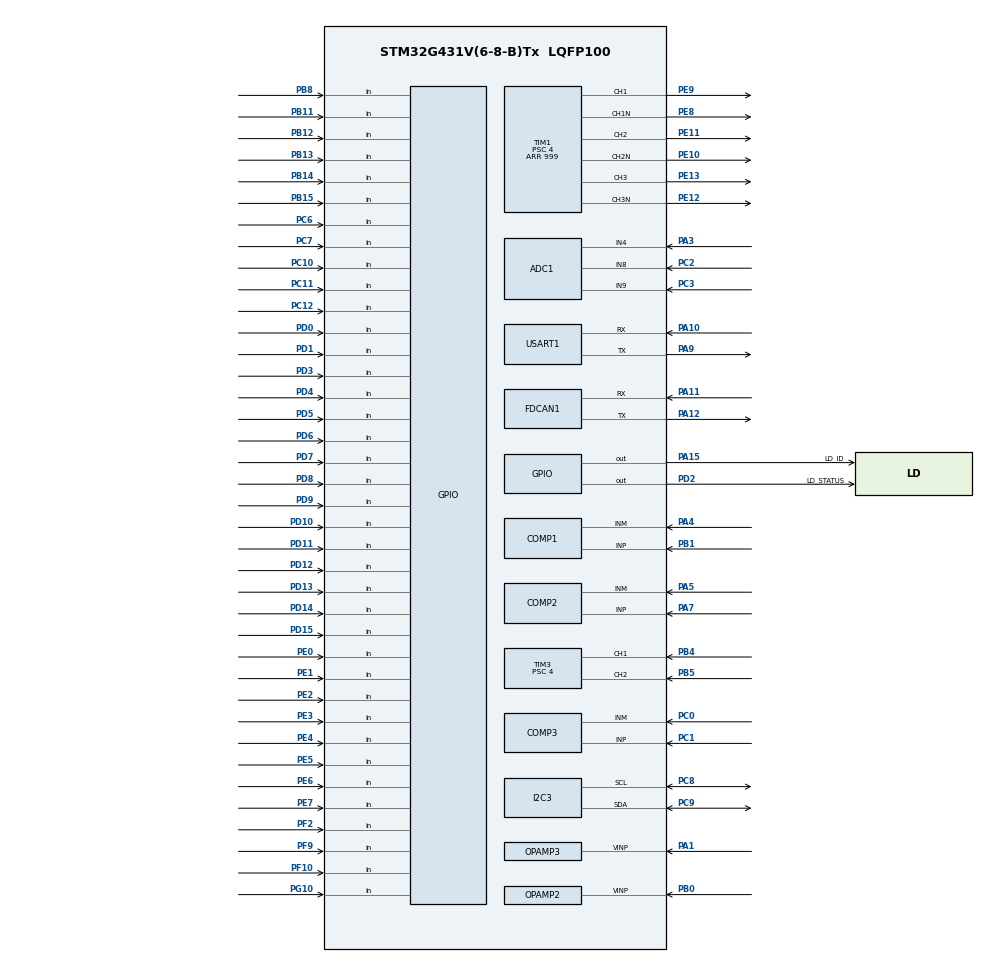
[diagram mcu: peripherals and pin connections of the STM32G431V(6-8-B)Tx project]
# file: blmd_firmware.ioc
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ADC1.Channel-4\#ChannelRegularConversion=ADC_CHANNEL_8
ADC1.Channel-5\#ChannelRegularConversion=ADC_CHANNEL_9
ADC1.Channel-6\#ChannelRegularConversion=ADC_CHANNEL_4
ADC1.ClockPrescaler=ADC_CLOCK_ASYNC_DIV8
ADC1.ContinuousConvMode=ENABLE
ADC1.DMAContinuousRequests=ENABLE
ADC1.EOCSelection=ADC_EOC_SEQ_CONV
ADC1.NbrOfConversion=3
ADC1.NbrOfConversionFlag=1
ADC1.OffsetNumber-4\#ChannelRegularConversion=ADC_OFFSET_NONE
ADC1.OffsetNumber-5\#ChannelRegularConversion=ADC_OFFSET_NONE
ADC1.OffsetNumber-6\#ChannelRegularConversion=ADC_OFFSET_NONE
ADC1.Rank-4\#ChannelRegularConversion=1
ADC1.Rank-5\#ChannelRegularConversion=2
ADC1.Rank-6\#ChannelRegularConversion=3
ADC1.SamplingTime-4\#ChannelRegularConversion=ADC_SAMPLETIME_12CYCLES_5
ADC1.SamplingTime-5\#ChannelRegularConversion=ADC_SAMPLETIME_12CYCLES_5
ADC1.SamplingTime-6\#ChannelRegularConversion=ADC_SAMPLETIME_12CYCLES_5
ADC1.master=1
ADC2.AWD1FilteringConfig=ADC_AWD_FILTERING_4SAMPLES
ADC2.AWD1HighThreshold=4000
ADC2.AWD1LowThreshold=96
ADC2.Channel-0\#ChannelRegularConversion=ADC_CHANNEL_VOPAMP2
ADC2.Channel-1\#ChannelRegularConversion=ADC_CHANNEL_VOPAMP3_ADC2
ADC2.ClockPrescaler=ADC_CLOCK_ASYNC_DIV8
ADC2.ContinuousConvMode=ENABLE
ADC2.DMAContinuousRequests=ENABLE
ADC2.EOCSelection=ADC_EOC_SEQ_CONV
ADC2.EnableAnalogWatchDog1=true
ADC2.EnableAnalogWatchDog2=false
ADC2.EnableAnalogWatchDog3=false
ADC2.NbrOfConversion=2
ADC2.NbrOfConversionFlag=1
ADC2.OffsetNumber-0\#ChannelRegularConversion=ADC_OFFSET_NONE
ADC2.OffsetNumber-1\#ChannelRegularConversion=ADC_OFFSET_NONE
ADC2.Rank-0\#ChannelRegularConversion=1
ADC2.Rank-1\#ChannelRegularConversion=2
ADC2.SamplingTime-0\#ChannelRegularConversion=ADC_SAMPLETIME_12CYCLES_5
ADC2.SamplingTime-1\#ChannelRegularConversion=ADC_SAMPLETIME_12CYCLES_5
ADC2.WatchdogMode=ADC_ANALOGWATCHDOG_ALL_REG
COMP1.BlankingSrce=COMP_BLANKINGSRC_NONE
COMP1.Hysteresis=COMP_HYSTERESIS_70MV
COMP1.TriggerMode=COMP_TRIGGERMODE_IT_RISING_FALLING
COMP2.BlankingSrce=COMP_BLANKINGSRC_NONE
COMP2.Hysteresis=COMP_HYSTERESIS_70MV
COMP2.TriggerMode=COMP_TRIGGERMODE_IT_RISING_FALLING
COMP3.BlankingSrce=COMP_BLANKINGSRC_NONE
COMP3.Hysteresis=COMP_HYSTERESIS_70MV
COMP3.TriggerMode=COMP_TRIGGERMODE_IT_RISING_FALLING
Dma.ADC1.0.Direction=DMA_PERIPH_TO_MEMORY
Dma.ADC1.0.EventEnable=DISABLE
Dma.ADC1.0.Instance=DMA1_Channel4
Dma.ADC1.0.MemDataAlignment=DMA_MDATAALIGN_HALFWORD
Dma.ADC1.0.MemInc=DMA_MINC_ENABLE
Dma.ADC1.0.Mode=DMA_CIRCULAR
Dma.ADC1.0.PeriphDataAlignment=DMA_PDATAALIGN_HALFWORD
Dma.ADC1.0.PeriphInc=DMA_PINC_DISABLE
Dma.ADC1.0.Polarity=HAL_DMAMUX_REQ_GEN_RISING
Dma.ADC1.0.Priority=DMA_PRIORITY_LOW
Dma.ADC1.0.RequestNumber=1
Dma.ADC1.0.SignalID=NONE
Dma.ADC1.0.SyncEnable=DISABLE
Dma.ADC1.0.SyncPolarity=HAL_DMAMUX_SYNC_NO_EVENT
Dma.ADC1.0.SyncRequestNumber=1
Dma.ADC1.0.SyncSignalID=NONE
Dma.ADC2.1.Direction=DMA_PERIPH_TO_MEMORY
Dma.ADC2.1.EventEnable=DISABLE
Dma.ADC2.1.Instance=DMA1_Channel1
Dma.ADC2.1.MemDataAlignment=DMA_MDATAALIGN_HALFWORD
Dma.ADC2.1.MemInc=DMA_MINC_ENABLE
Dma.ADC2.1.Mode=DMA_CIRCULAR
Dma.ADC2.1.PeriphDataAlignment=DMA_PDATAALIGN_HALFWORD
Dma.ADC2.1.PeriphInc=DMA_PINC_DISABLE
Dma.ADC2.1.Polarity=HAL_DMAMUX_REQ_GEN_RISING
Dma.ADC2.1.Priority=DMA_PRIORITY_LOW
Dma.ADC2.1.RequestNumber=1
Dma.ADC2.1.SignalID=NONE
Dma.ADC2.1.SyncEnable=DISABLE
Dma.ADC2.1.SyncPolarity=HAL_DMAMUX_SYNC_NO_EVENT
Dma.ADC2.1.SyncRequestNumber=1
Dma.ADC2.1.SyncSignalID=NONE
Dma.FMAC_READ.2.Direction=DMA_PERIPH_TO_MEMORY
Dma.FMAC_READ.2.EventEnable=DISABLE
Dma.FMAC_READ.2.Instance=DMA1_Channel3
Dma.FMAC_READ.2.MemDataAlignment=DMA_MDATAALIGN_HALFWORD
Dma.FMAC_READ.2.MemInc=DMA_MINC_ENABLE
Dma.FMAC_READ.2.Mode=DMA_CIRCULAR
Dma.FMAC_READ.2.PeriphDataAlignment=DMA_PDATAALIGN_WORD
Dma.FMAC_READ.2.PeriphInc=DMA_PINC_DISABLE
Dma.FMAC_READ.2.Polarity=HAL_DMAMUX_REQ_GEN_RISING
Dma.FMAC_READ.2.Priority=DMA_PRIORITY_LOW
Dma.FMAC_READ.2.RequestNumber=1
Dma.FMAC_READ.2.SignalID=NONE
Dma.FMAC_READ.2.SyncEnable=DISABLE
Dma.FMAC_READ.2.SyncPolarity=HAL_DMAMUX_SYNC_NO_EVENT
Dma.FMAC_READ.2.SyncRequestNumber=1
Dma.FMAC_READ.2.SyncSignalID=NONE
Dma.FMAC_WRITE.3.Direction=DMA_MEMORY_TO_PERIPH
Dma.FMAC_WRITE.3.EventEnable=DISABLE
Dma.FMAC_WRITE.3.Instance=DMA1_Channel2
Dma.FMAC_WRITE.3.MemDataAlignment=DMA_MDATAALIGN_HALFWORD
Dma.FMAC_WRITE.3.MemInc=DMA_MINC_ENABLE
Dma.FMAC_WRITE.3.Mode=DMA_NORMAL
Dma.FMAC_WRITE.3.PeriphDataAlignment=DMA_PDATAALIGN_WORD
Dma.FMAC_WRITE.3.PeriphInc=DMA_PINC_DISABLE
Dma.FMAC_WRITE.3.Polarity=HAL_DMAMUX_REQ_GEN_RISING
Dma.FMAC_WRITE.3.Priority=DMA_PRIORITY_LOW
Dma.FMAC_WRITE.3.RequestNumber=1
Dma.FMAC_WRITE.3.SignalID=NONE
Dma.FMAC_WRITE.3.SyncEnable=DISABLE
Dma.FMAC_WRITE.3.SyncPolarity=HAL_DMAMUX_SYNC_NO_EVENT
Dma.FMAC_WRITE.3.SyncRequestNumber=1
Dma.FMAC_WRITE.3.SyncSignalID=NONE
Dma.Request0=ADC1
Dma.Request1=ADC2
Dma.Request2=FMAC_READ
Dma.Request3=FMAC_WRITE
FDCAN1.CalculateBaudRateNominal=1000000
FDCAN1.CalculateTimeBitNominal=1000
FDCAN1.CalculateTimeQuantumNominal=100.0
FDCAN1.NominalTimeSeg1=6
FDCAN1.NominalTimeSeg2=3
I2C3.Timing=0x30D29DE4
Mcu.Family=STM32G4
Mcu.Name=STM32G431V(6-8-B)Tx
Mcu.Package=LQFP100
NVIC.COMP1_2_3_IRQn=true\:0\:0\:false\:false\:true\:false\:true\:true
NVIC.PriorityGroup=NVIC_PRIORITYGROUP_4
NVIC.TIM1_UP_TIM16_IRQn=true\:0\:0\:false\:false\:true\:true\:true\:true
NVIC.TIM6_DAC_IRQn=true\:0\:0\:false\:false\:true\:true\:true\:true
PA1.Mode=PGA_Internally_Connected
PA1.Signal=OPAMP3_VINP
PA10.Mode=Asynchronous
PA10.Signal=USART1_RX
PA11.Mode=FDCAN_Activate
PA11.Signal=FDCAN1_RX
PA12.Mode=FDCAN_Activate
PA12.Signal=FDCAN1_TX
PA13.Mode=Trace_Asynchronous_SW
PA13.Signal=SYS_JTMS-SWDIO
PA14.Mode=Trace_Asynchronous_SW
PA14.Signal=SYS_JTCK-SWCLK
PA15.GPIO_Label=LD_ID
PA15.Signal=GPIO_Output
PA3.Mode=IN4-Single-Ended
PA3.Signal=ADC1_IN4
PA4.Mode=INM
PA4.Signal=COMP1_INM
PA5.Mode=INM
PA5.Signal=COMP2_INM
PA7.Mode=INP
PA7.Signal=COMP2_INP
PA9.Mode=Asynchronous
PA9.Signal=USART1_TX
PB0.Mode=Follower_Internally_Connected
PB0.Signal=OPAMP2_VINP
PB1.Mode=INP
PB1.Signal=COMP1_INP
PB11.Signal=GPIO_Input
PB12.Signal=GPIO_Input
PB13.Signal=GPIO_Input
PB14.Signal=GPIO_Input
PB15.Signal=GPIO_Input
PB3.Mode=Trace_Asynchronous_SW
PB3.Signal=SYS_JTDO-SWO
PB4.Signal=S_TIM3_CH1
PB5.Signal=S_TIM3_CH2
PB8-BOOT0.Signal=GPIO_Input
PC0.Mode=INM
PC0.Signal=COMP3_INM
PC1.Mode=INP
PC1.Signal=COMP3_INP
PC10.Signal=GPIO_Input
PC11.Signal=GPIO_Input
PC12.Signal=GPIO_Input
PC2.Mode=IN8-Single-Ended
PC2.Signal=ADC1_IN8
PC3.Mode=IN9-Single-Ended
PC3.Signal=ADC1_IN9
PC6.Signal=GPIO_Input
PC7.Signal=GPIO_Input
PC8.Mode=I2C
PC8.Signal=I2C3_SCL
PC9.Mode=I2C
PC9.Signal=I2C3_SDA
PD0.Signal=GPIO_Input
PD1.Signal=GPIO_Input
PD10.Signal=GPIO_Input
PD11.Signal=GPIO_Input
PD12.Signal=GPIO_Input
PD13.Signal=GPIO_Input
PD14.Signal=GPIO_Input
PD15.Signal=GPIO_Input
PD2.GPIO_Label=LD_STATUS
PD2.Signal=GPIO_Output
PD3.Signal=GPIO_Input
PD4.Signal=GPIO_Input
PD5.Signal=GPIO_Input
PD6.Signal=GPIO_Input
PD7.Signal=GPIO_Input
PD8.Signal=GPIO_Input
PD9.Signal=GPIO_Input
PE0.Signal=GPIO_Input
PE1.Signal=GPIO_Input
PE10.Mode=PWM Generation2 CH2 CH2N
PE10.Signal=TIM1_CH2N
PE11.Signal=S_TIM1_CH2
PE12.Mode=PWM Generation3 CH3 CH3N
PE12.Signal=TIM1_CH3N
PE13.Signal=S_TIM1_CH3
PE2.Signal=GPIO_Input
PE3.Signal=GPIO_Input
PE4.Signal=GPIO_Input
PE5.Signal=GPIO_Input
PE6.Signal=GPIO_Input
PE7.Signal=GPIO_Input
PE8.Mode=PWM Generation1 CH1 CH1N
PE8.Signal=TIM1_CH1N
PE9.Signal=S_TIM1_CH1
PF10.Signal=GPIO_Input
PF2.Signal=GPIO_Input
PF9.Signal=GPIO_Input
PG10-NRST.Signal=GPIO_Input
ProjectManager.HeapSize=0x200
ProjectManager.StackSize=0x400
ProjectManager.TargetToolchain=CMake
RCC.ADC12Freq_Value=160000000
RCC.AHBFreq_Value=160000000
RCC.APB1Freq_Value=160000000
RCC.APB1TimFreq_Value=160000000
RCC.APB2Freq_Value=160000000
RCC.APB2TimFreq_Value=160000000
RCC.CortexFreq_Value=160000000
RCC.EXTERNAL_CLOCK_VALUE=12288000
RCC.HCLKFreq_Value=160000000
RCC.HSE_VALUE=8000000
RCC.HSI48_VALUE=48000000
RCC.HSI_VALUE=16000000
RCC.LSE_VALUE=32768
RCC.PLLN=20
RCC.SYSCLKFreq_VALUE=160000000
RCC.SYSCLKSource=RCC_SYSCLKSOURCE_PLLCLK
RCC.USBFreq_Value=160000000
RCC.VCOOutputFreq_Value=320000000
SH.S_TIM1_CH1.0=TIM1_CH1,PWM Generation1 CH1 CH1N
SH.S_TIM1_CH2.0=TIM1_CH2,PWM Generation2 CH2 CH2N
SH.S_TIM1_CH3.0=TIM1_CH3,PWM Generation3 CH3 CH3N
SH.S_TIM3_CH1.0=TIM3_CH1,Input_Capture1_from_TI1
SH.S_TIM3_CH2.0=TIM3_CH2,Input_Capture2_from_TI2
TIM1.Channel-PWM\ Generation1\ CH1\ CH1N=TIM_CHANNEL_1
TIM1.Channel-PWM\ Generation2\ CH2\ CH2N=TIM_CHANNEL_2
TIM1.Channel-PWM\ Generation3\ CH3\ CH3N=TIM_CHANNEL_3
TIM1.DeadTime=128
TIM1.PeriodNoDither=999
TIM1.Prescaler=4
TIM1.TIM_MasterOutputTrigger=TIM_TRGO_RESET
TIM3.Channel-Input_Capture1_from_TI1=TIM_CHANNEL_1
TIM3.Channel-Input_Capture2_from_TI2=TIM_CHANNEL_2
TIM3.PeriodNoDither=999
TIM3.Prescaler=4
TIM6.PeriodNoDither=999
TIM6.Prescaler=4
USART1.VirtualMode-Asynchronous=VM_ASYNC
VP_ADC2_OPAMP_INTERNAL2.Mode=IN-OPAMP2
VP_ADC2_OPAMP_INTERNAL3.Mode=IN-OPAMP3
VP_CORDIC_VS_CORDIC.Mode=CORDIC_Activate
VP_FMAC_VS_FMAC.Mode=FMAC_Activate
VP_SYS_VS_DBSignals.Mode=DisableDeadBatterySignals
VP_TIM6_VS_ClockSourceINT.Mode=Enable_Timer
board=custom

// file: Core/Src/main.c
/* USER CODE BEGIN Header */
/**
  ******************************************************************************
  * @file           : main.c
  * @brief          : Main program body
  ******************************************************************************
  * @attention
  *
  * Copyright (c) 2024 STMicroelectronics.
  * All rights reserved.
  *
  * This software is licensed under terms that can be found in the LICENSE file
  * in the root directory of this software component.
  * If no LICENSE file comes with this software, it is provided AS-IS.
  *
  ******************************************************************************
  */
/* USER CODE END Header */
#include "main.h"

/* USER CODE BEGIN Includes */
#include "stdio.h"
#include "stdlib.h"
#include "math.h"

#include "foc.h"
/* USER CODE END Includes */

/* USER CODE BEGIN PD */
#define I2C_ADD 0x47
/* USER CODE END PD */

FDCAN_HandleTypeDef hfdcan1;

/* USER CODE BEGIN PV */
/* for PI control valuables */
RingBuf pi_u;		//control values
RingBuf pi_e;		//deviation
RingBuf omg_est;	//omg estimate

volatile int32_t omg_tgt = 0;		//fixed float 22.10[rad/ms]
volatile int32_t adv_ang = 0;		//fixed float 22.10[rad]
volatile int32_t rot_est = 0;		//fixed float 22.10[rad]

volatile int32_t omg_est2 = 0;		//fixed float 22.10[rad/ms]
volatile int32_t rot_est2 = 0;		//fixed float 22.10[rad]

volatile uint8_t rot_direct = 0;

/* for FMAC valuables */
volatile uint16_t adc_datas[ADC_BUF] = {0u};
volatile uint16_t y_buffer[2] = {0u};
float current[2] = {0u};
uint8_t dma_index = 0u;
uint32_t detect_flag = 0;
/* USER CODE END PV */

void SystemClock_Config(void);
static void MX_GPIO_Init(void);
static void MX_DMA_Init(void);
static void MX_COMP1_Init(void);
static void MX_COMP2_Init(void);
static void MX_COMP3_Init(void);
static void MX_OPAMP2_Init(void);
static void MX_FDCAN1_Init(void);
static void MX_USART1_UART_Init(void);
static void MX_ADC1_Init(void);
static void MX_ADC2_Init(void);
static void MX_I2C3_Init(void);
static void MX_OPAMP3_Init(void);
static void MX_TIM1_Init(void);
static void MX_TIM3_Init(void);
static void MX_CORDIC_Init(void);
static void MX_FMAC_Init(void);
static void MX_TIM6_Init(void);

int main(void)
{

  /* USER CODE BEGIN 1 */

	pi_u.pnt = 0;
	pi_e.pnt = 0;
	for(int8_t i = 0; i<4;i++){
		pi_u.data[i] = 100<<10;
		pi_e.data[i] = 0;
	}
  /* USER CODE END 1 */

  /* MCU Configuration--------------------------------------------------------*/

  /* Reset of all peripherals, Initializes the Flash interface and the Systick. */
  HAL_Init();

  /* Configure the system clock */
  SystemClock_Config();

  /* Initialize all configured peripherals */
  MX_GPIO_Init();
  MX_DMA_Init();
  MX_COMP1_Init();
  MX_COMP2_Init();
  MX_COMP3_Init();
  MX_OPAMP2_Init();
  MX_FDCAN1_Init();
  MX_USART1_UART_Init();
  MX_ADC1_Init();
  MX_ADC2_Init();
  MX_I2C3_Init();
  MX_OPAMP3_Init();
  MX_TIM1_Init();
  MX_TIM3_Init();
  MX_CORDIC_Init();
  MX_FMAC_Init();
  MX_TIM6_Init();
  /* USER CODE BEGIN 2 */
	adc_setup();

	LL_OPAMP_Enable(OPAMP2);
	LL_OPAMP_Enable(OPAMP3);

	LL_COMP_Enable(COMP1);
	LL_COMP_Enable(COMP2);
	LL_COMP_Enable(COMP3);

	LL_TIM_EnableCounter(TIM1);
	LL_TIM_EnableARRPreload(TIM1);
	LL_TIM_EnableAllOutputs(TIM1);

	LL_TIM_CC_EnableChannel(TIM1, LL_TIM_CHANNEL_CH1);
	LL_TIM_CC_EnableChannel(TIM1, LL_TIM_CHANNEL_CH1N);
	LL_TIM_OC_SetCompareCH1(TIM1, 200);

	// start gate driver
	LL_I2C_Enable(I2C3);

	LL_I2C_HandleTransfer(I2C3, 0x47, LL_I2C_ADDRESSING_MODE_7BIT, 1, LL_I2C_MODE_AUTOEND, LL_I2C_GENERATE_START_WRITE);
	while(!LL_I2C_IsActiveFlag_TXE(I2C3));
	LL_I2C_TransmitData8(I2C3, 0x80);

	LL_I2C_HandleTransfer(I2C3, 0x47, LL_I2C_ADDRESSING_MODE_7BIT, 1, LL_I2C_MODE_AUTOEND, LL_I2C_GENERATE_START_READ);
	while(LL_I2C_IsActiveFlag_RXNE(I2C3));
	uint8_t i2c_buf = LL_I2C_ReceiveData8(I2C3);

	if(i2c_buf & 0x04){
		LL_GPIO_SetOutputPin(LD_ID_GPIO_Port, LD_ID_Pin);
	}

	LL_mDelay(1000);

	startSequence();

	LL_mDelay(2000);

	rot_direct = 0;
	omg_tgt = (uint32_t)(45.0*M_PI/100.0f * 1024.0f);
  	omg_est2 = (uint32_t)(7.0*M_PI/100.0f * 1024.0f);
	adv_ang = (uint32_t)(0.0*M_PI/180.0f * 1024);
	rot_est2 = (uint32_t)( 60*M_PI/180*1024);
	detect_flag = 1;
	LL_EXTI_DisableRisingTrig_0_31(LL_EXTI_LINE_21);
	LL_EXTI_DisableFallingTrig_0_31(LL_EXTI_LINE_21);
	LL_EXTI_DisableRisingTrig_0_31(LL_EXTI_LINE_22);
	LL_EXTI_DisableFallingTrig_0_31(LL_EXTI_LINE_22);
	LL_EXTI_DisableRisingTrig_0_31(LL_EXTI_LINE_29);
	LL_EXTI_DisableFallingTrig_0_31(LL_EXTI_LINE_29);
	LL_TIM_EnableCounter(TIM6);
	LL_TIM_EnableIT_UPDATE(TIM6);
  /* USER CODE END 2 */

  /* Infinite loop */
  /* USER CODE BEGIN WHILE */
  while (1)
  {
	LL_mDelay(300);
	if(omg_est2 <= omg_tgt*5/6){
		omg_est2 += omg_tgt/10;
	}

	if((omg_tgt-omg_est.data[(omg_est.pnt+3)&0x03]) < 50){
		LL_GPIO_TogglePin(LD_STATUS_GPIO_Port, LD_STATUS_Pin);
	}
//	LL_I2C_HandleTransfer(I2C3, 0x47, LL_I2C_ADDRESSING_MODE_7BIT, 1, LL_I2C_MODE_AUTOEND, LL_I2C_GENERATE_START_WRITE);
//	while(!LL_I2C_IsActiveFlag_TXE(I2C3));
//	LL_I2C_TransmitData8(I2C3, 0x80);
//
//	LL_I2C_HandleTransfer(I2C3, 0x47, LL_I2C_ADDRESSING_MODE_7BIT, 1, LL_I2C_MODE_AUTOEND, LL_I2C_GENERATE_START_READ);
//	while(LL_I2C_IsActiveFlag_RXNE(I2C3));
//	i2c_buf = LL_I2C_ReceiveData8(I2C3);
//
//	if(i2c_buf){
//		LL_GPIO_SetOutputPin(LD_ID_GPIO_Port, LD_ID_Pin);
//	}

	char str[16];
	sprintf(str, "%d\n" , (int)(omg_est.data[0]+omg_est.data[1]+omg_est.data[2]+omg_est.data[3])>>2);
	for(uint8_t i=0;str[i] != '\0'; i++){
		ITM_SendChar(str[i]);
	}
    /* USER CODE END WHILE */

  }
}

void SystemClock_Config(void)
{
  LL_FLASH_SetLatency(LL_FLASH_LATENCY_4);
  while(LL_FLASH_GetLatency() != LL_FLASH_LATENCY_4)
  {
  }
  LL_PWR_EnableRange1BoostMode();
  LL_RCC_HSI_Enable();
   /* Wait till HSI is ready */
  while(LL_RCC_HSI_IsReady() != 1)
  {
  }

  LL_RCC_HSI_SetCalibTrimming(64);
  LL_RCC_PLL_ConfigDomain_SYS(LL_RCC_PLLSOURCE_HSI, LL_RCC_PLLM_DIV_1, 20, LL_RCC_PLLR_DIV_2);
  LL_RCC_PLL_EnableDomain_SYS();
  LL_RCC_PLL_Enable();
   /* Wait till PLL is ready */
  while(LL_RCC_PLL_IsReady() != 1)
  {
  }

  LL_RCC_SetSysClkSource(LL_RCC_SYS_CLKSOURCE_PLL);
  LL_RCC_SetAHBPrescaler(LL_RCC_SYSCLK_DIV_2);
   /* Wait till System clock is ready */
  while(LL_RCC_GetSysClkSource() != LL_RCC_SYS_CLKSOURCE_STATUS_PLL)
  {
  }

  /* Insure 1us transition state at intermediate medium speed clock*/
  for (__IO uint32_t i = (170 >> 1); i !=0; i--);

  /* Set AHB prescaler*/
  LL_RCC_SetAHBPrescaler(LL_RCC_SYSCLK_DIV_1);
  LL_RCC_SetAPB1Prescaler(LL_RCC_APB1_DIV_1);
  LL_RCC_SetAPB2Prescaler(LL_RCC_APB2_DIV_1);
  LL_SetSystemCoreClock(160000000);

   /* Update the time base */
  if (HAL_InitTick (TICK_INT_PRIORITY) != HAL_OK)
  {
    Error_Handler();
  }
}

static void MX_ADC1_Init(void)
{

  LL_ADC_InitTypeDef ADC_InitStruct = {0};
  LL_ADC_REG_InitTypeDef ADC_REG_InitStruct = {0};
  LL_ADC_CommonInitTypeDef ADC_CommonInitStruct = {0};

  LL_GPIO_InitTypeDef GPIO_InitStruct = {0};

  LL_RCC_SetADCClockSource(LL_RCC_ADC12_CLKSOURCE_SYSCLK);

  /* Peripheral clock enable */
  LL_AHB2_GRP1_EnableClock(LL_AHB2_GRP1_PERIPH_ADC12);

  LL_AHB2_GRP1_EnableClock(LL_AHB2_GRP1_PERIPH_GPIOC);
  LL_AHB2_GRP1_EnableClock(LL_AHB2_GRP1_PERIPH_GPIOA);
  /**ADC1 GPIO Configuration
  PC2   ------> ADC1_IN8
  PC3   ------> ADC1_IN9
  PA3   ------> ADC1_IN4
  */
  GPIO_InitStruct.Pin = LL_GPIO_PIN_2;
  GPIO_InitStruct.Mode = LL_GPIO_MODE_ANALOG;
  GPIO_InitStruct.Pull = LL_GPIO_PULL_NO;
  LL_GPIO_Init(GPIOC, &GPIO_InitStruct);

  GPIO_InitStruct.Pin = LL_GPIO_PIN_3;
  GPIO_InitStruct.Mode = LL_GPIO_MODE_ANALOG;
  GPIO_InitStruct.Pull = LL_GPIO_PULL_NO;
  LL_GPIO_Init(GPIOC, &GPIO_InitStruct);

  GPIO_InitStruct.Pin = LL_GPIO_PIN_3;
  GPIO_InitStruct.Mode = LL_GPIO_MODE_ANALOG;
  GPIO_InitStruct.Pull = LL_GPIO_PULL_NO;
  LL_GPIO_Init(GPIOA, &GPIO_InitStruct);

  /* ADC1 DMA Init */

  /* ADC1 Init */
  LL_DMA_SetPeriphRequest(DMA1, LL_DMA_CHANNEL_4, LL_DMAMUX_REQ_ADC1);

  LL_DMA_SetDataTransferDirection(DMA1, LL_DMA_CHANNEL_4, LL_DMA_DIRECTION_PERIPH_TO_MEMORY);

  LL_DMA_SetChannelPriorityLevel(DMA1, LL_DMA_CHANNEL_4, LL_DMA_PRIORITY_LOW);

  LL_DMA_SetMode(DMA1, LL_DMA_CHANNEL_4, LL_DMA_MODE_CIRCULAR);

  LL_DMA_SetPeriphIncMode(DMA1, LL_DMA_CHANNEL_4, LL_DMA_PERIPH_NOINCREMENT);

  LL_DMA_SetMemoryIncMode(DMA1, LL_DMA_CHANNEL_4, LL_DMA_MEMORY_INCREMENT);

  LL_DMA_SetPeriphSize(DMA1, LL_DMA_CHANNEL_4, LL_DMA_PDATAALIGN_HALFWORD);

  LL_DMA_SetMemorySize(DMA1, LL_DMA_CHANNEL_4, LL_DMA_MDATAALIGN_HALFWORD);

  /** Common config
  */
  ADC_InitStruct.Resolution = LL_ADC_RESOLUTION_12B;
  ADC_InitStruct.DataAlignment = LL_ADC_DATA_ALIGN_RIGHT;
  ADC_InitStruct.LowPowerMode = LL_ADC_LP_MODE_NONE;
  LL_ADC_Init(ADC1, &ADC_InitStruct);
  ADC_REG_InitStruct.TriggerSource = LL_ADC_REG_TRIG_SOFTWARE;
  ADC_REG_InitStruct.SequencerLength = LL_ADC_REG_SEQ_SCAN_ENABLE_3RANKS;
  ADC_REG_InitStruct.SequencerDiscont = LL_ADC_REG_SEQ_DISCONT_DISABLE;
  ADC_REG_InitStruct.ContinuousMode = LL_ADC_REG_CONV_CONTINUOUS;
  ADC_REG_InitStruct.DMATransfer = LL_ADC_REG_DMA_TRANSFER_UNLIMITED;
  ADC_REG_InitStruct.Overrun = LL_ADC_REG_OVR_DATA_PRESERVED;
  LL_ADC_REG_Init(ADC1, &ADC_REG_InitStruct);
  LL_ADC_SetGainCompensation(ADC1, 0);
  LL_ADC_SetOverSamplingScope(ADC1, LL_ADC_OVS_DISABLE);
  ADC_CommonInitStruct.CommonClock = LL_ADC_CLOCK_ASYNC_DIV8;
  ADC_CommonInitStruct.Multimode = LL_ADC_MULTI_INDEPENDENT;
  LL_ADC_CommonInit(__LL_ADC_COMMON_INSTANCE(ADC1), &ADC_CommonInitStruct);

  /* Disable ADC deep power down (enabled by default after reset state) */
  LL_ADC_DisableDeepPowerDown(ADC1);
  /* Enable ADC internal voltage regulator */
  LL_ADC_EnableInternalRegulator(ADC1);
  /* Delay for ADC internal voltage regulator stabilization. */
  /* Compute number of CPU cycles to wait for, from delay in us. */
  /* Note: Variable divided by 2 to compensate partially */
  /* CPU processing cycles (depends on compilation optimization). */
  /* Note: If system core clock frequency is below 200kHz, wait time */
  /* is only a few CPU processing cycles. */
  uint32_t wait_loop_index;
  wait_loop_index = ((LL_ADC_DELAY_INTERNAL_REGUL_STAB_US * (SystemCoreClock / (100000 * 2))) / 10);
  while(wait_loop_index != 0)
  {
    wait_loop_index--;
  }

  /** Configure Regular Channel
  */
  LL_ADC_REG_SetSequencerRanks(ADC1, LL_ADC_REG_RANK_1, LL_ADC_CHANNEL_8);
  LL_ADC_SetChannelSamplingTime(ADC1, LL_ADC_CHANNEL_8, LL_ADC_SAMPLINGTIME_12CYCLES_5);
  LL_ADC_SetChannelSingleDiff(ADC1, LL_ADC_CHANNEL_8, LL_ADC_SINGLE_ENDED);

  /** Configure Regular Channel
  */
  LL_ADC_REG_SetSequencerRanks(ADC1, LL_ADC_REG_RANK_2, LL_ADC_CHANNEL_9);
  LL_ADC_SetChannelSamplingTime(ADC1, LL_ADC_CHANNEL_9, LL_ADC_SAMPLINGTIME_12CYCLES_5);
  LL_ADC_SetChannelSingleDiff(ADC1, LL_ADC_CHANNEL_9, LL_ADC_SINGLE_ENDED);

  /** Configure Regular Channel
  */
  LL_ADC_REG_SetSequencerRanks(ADC1, LL_ADC_REG_RANK_3, LL_ADC_CHANNEL_4);
  LL_ADC_SetChannelSamplingTime(ADC1, LL_ADC_CHANNEL_4, LL_ADC_SAMPLINGTIME_12CYCLES_5);
  LL_ADC_SetChannelSingleDiff(ADC1, LL_ADC_CHANNEL_4, LL_ADC_SINGLE_ENDED);

}

static void MX_ADC2_Init(void)
{

  LL_ADC_InitTypeDef ADC_InitStruct = {0};
  LL_ADC_REG_InitTypeDef ADC_REG_InitStruct = {0};

  LL_RCC_SetADCClockSource(LL_RCC_ADC12_CLKSOURCE_SYSCLK);

  /* Peripheral clock enable */
  LL_AHB2_GRP1_EnableClock(LL_AHB2_GRP1_PERIPH_ADC12);

  /* ADC2 DMA Init */

  /* ADC2 Init */
  LL_DMA_SetPeriphRequest(DMA1, LL_DMA_CHANNEL_1, LL_DMAMUX_REQ_ADC2);

  LL_DMA_SetDataTransferDirection(DMA1, LL_DMA_CHANNEL_1, LL_DMA_DIRECTION_PERIPH_TO_MEMORY);

  LL_DMA_SetChannelPriorityLevel(DMA1, LL_DMA_CHANNEL_1, LL_DMA_PRIORITY_LOW);

  LL_DMA_SetMode(DMA1, LL_DMA_CHANNEL_1, LL_DMA_MODE_CIRCULAR);

  LL_DMA_SetPeriphIncMode(DMA1, LL_DMA_CHANNEL_1, LL_DMA_PERIPH_NOINCREMENT);

  LL_DMA_SetMemoryIncMode(DMA1, LL_DMA_CHANNEL_1, LL_DMA_MEMORY_INCREMENT);

  LL_DMA_SetPeriphSize(DMA1, LL_DMA_CHANNEL_1, LL_DMA_PDATAALIGN_HALFWORD);

  LL_DMA_SetMemorySize(DMA1, LL_DMA_CHANNEL_1, LL_DMA_MDATAALIGN_HALFWORD);

  /** Common config
  */
  ADC_InitStruct.Resolution = LL_ADC_RESOLUTION_12B;
  ADC_InitStruct.DataAlignment = LL_ADC_DATA_ALIGN_RIGHT;
  ADC_InitStruct.LowPowerMode = LL_ADC_LP_MODE_NONE;
  LL_ADC_Init(ADC2, &ADC_InitStruct);
  ADC_REG_InitStruct.TriggerSource = LL_ADC_REG_TRIG_SOFTWARE;
  ADC_REG_InitStruct.SequencerLength = LL_ADC_REG_SEQ_SCAN_ENABLE_2RANKS;
  ADC_REG_InitStruct.SequencerDiscont = LL_ADC_REG_SEQ_DISCONT_DISABLE;
  ADC_REG_InitStruct.ContinuousMode = LL_ADC_REG_CONV_CONTINUOUS;
  ADC_REG_InitStruct.DMATransfer = LL_ADC_REG_DMA_TRANSFER_UNLIMITED;
  ADC_REG_InitStruct.Overrun = LL_ADC_REG_OVR_DATA_PRESERVED;
  LL_ADC_REG_Init(ADC2, &ADC_REG_InitStruct);
  LL_ADC_SetGainCompensation(ADC2, 0);
  LL_ADC_SetOverSamplingScope(ADC2, LL_ADC_OVS_DISABLE);

  /* Disable ADC deep power down (enabled by default after reset state) */
  LL_ADC_DisableDeepPowerDown(ADC2);
  /* Enable ADC internal voltage regulator */
  LL_ADC_EnableInternalRegulator(ADC2);
  /* Delay for ADC internal voltage regulator stabilization. */
  /* Compute number of CPU cycles to wait for, from delay in us. */
  /* Note: Variable divided by 2 to compensate partially */
  /* CPU processing cycles (depends on compilation optimization). */
  /* Note: If system core clock frequency is below 200kHz, wait time */
  /* is only a few CPU processing cycles. */
  uint32_t wait_loop_index;
  wait_loop_index = ((LL_ADC_DELAY_INTERNAL_REGUL_STAB_US * (SystemCoreClock / (100000 * 2))) / 10);
  while(wait_loop_index != 0)
  {
    wait_loop_index--;
  }

  /** Configure Analog WatchDog 1
  */
  LL_ADC_SetAnalogWDMonitChannels(ADC2, LL_ADC_AWD1, LL_ADC_AWD_ALL_CHANNELS_REG);
  LL_ADC_ConfigAnalogWDThresholds(ADC2, LL_ADC_AWD1, 4000, 96);
  LL_ADC_SetAWDFilteringConfiguration(ADC2, LL_ADC_AWD1, LL_ADC_AWD_FILTERING_4SAMPLES);
  LL_ADC_DisableIT_AWD1(ADC2);

  /** Configure Regular Channel
  */
  LL_ADC_REG_SetSequencerRanks(ADC2, LL_ADC_REG_RANK_1, LL_ADC_CHANNEL_VOPAMP2);
  LL_ADC_SetChannelSamplingTime(ADC2, LL_ADC_CHANNEL_VOPAMP2, LL_ADC_SAMPLINGTIME_12CYCLES_5);
  LL_ADC_SetChannelSingleDiff(ADC2, LL_ADC_CHANNEL_VOPAMP2, LL_ADC_SINGLE_ENDED);

  /** Configure Regular Channel
  */
  LL_ADC_REG_SetSequencerRanks(ADC2, LL_ADC_REG_RANK_2, LL_ADC_CHANNEL_VOPAMP3_ADC2);
  LL_ADC_SetChannelSamplingTime(ADC2, LL_ADC_CHANNEL_VOPAMP3_ADC2, LL_ADC_SAMPLINGTIME_12CYCLES_5);
  LL_ADC_SetChannelSingleDiff(ADC2, LL_ADC_CHANNEL_VOPAMP3_ADC2, LL_ADC_SINGLE_ENDED);

}

static void MX_COMP1_Init(void)
{

  LL_COMP_InitTypeDef COMP_InitStruct = {0};

  LL_GPIO_InitTypeDef GPIO_InitStruct = {0};

  LL_AHB2_GRP1_EnableClock(LL_AHB2_GRP1_PERIPH_GPIOA);
  LL_AHB2_GRP1_EnableClock(LL_AHB2_GRP1_PERIPH_GPIOB);
  /**COMP1 GPIO Configuration
  PA4   ------> COMP1_INM
  PB1   ------> COMP1_INP
  */
  GPIO_InitStruct.Pin = LL_GPIO_PIN_4;
  GPIO_InitStruct.Mode = LL_GPIO_MODE_ANALOG;
  GPIO_InitStruct.Pull = LL_GPIO_PULL_NO;
  LL_GPIO_Init(GPIOA, &GPIO_InitStruct);

  GPIO_InitStruct.Pin = LL_GPIO_PIN_1;
  GPIO_InitStruct.Mode = LL_GPIO_MODE_ANALOG;
  GPIO_InitStruct.Pull = LL_GPIO_PULL_NO;
  LL_GPIO_Init(GPIOB, &GPIO_InitStruct);

  /* COMP1 interrupt Init */
  NVIC_SetPriority(COMP1_2_3_IRQn, NVIC_EncodePriority(NVIC_GetPriorityGrouping(),0, 0));
  NVIC_EnableIRQ(COMP1_2_3_IRQn);

  COMP_InitStruct.InputPlus = LL_COMP_INPUT_PLUS_IO2;
  COMP_InitStruct.InputMinus = LL_COMP_INPUT_MINUS_IO1;
  COMP_InitStruct.InputHysteresis = LL_COMP_HYSTERESIS_70MV;
  COMP_InitStruct.OutputPolarity = LL_COMP_OUTPUTPOL_NONINVERTED;
  COMP_InitStruct.OutputBlankingSource = LL_COMP_BLANKINGSRC_NONE;
  LL_COMP_Init(COMP1, &COMP_InitStruct);

  /* Wait loop initialization and execution */
  /* Note: Variable divided by 2 to compensate partially CPU processing cycles */
  __IO uint32_t wait_loop_index = 0;
  wait_loop_index = (LL_COMP_DELAY_VOLTAGE_SCALER_STAB_US * (SystemCoreClock / (1000000 * 2)));
  while(wait_loop_index != 0)
  {
    wait_loop_index--;
  }
  LL_EXTI_EnableFallingTrig_0_31(LL_EXTI_LINE_21);
  LL_EXTI_EnableRisingTrig_0_31(LL_EXTI_LINE_21);
  LL_EXTI_ClearFlag_0_31(LL_EXTI_LINE_21);
  LL_EXTI_DisableEvent_0_31(LL_EXTI_LINE_21);
  LL_EXTI_EnableIT_0_31(LL_EXTI_LINE_21);

}

static void MX_COMP2_Init(void)
{

  LL_COMP_InitTypeDef COMP_InitStruct = {0};

  LL_GPIO_InitTypeDef GPIO_InitStruct = {0};

  LL_AHB2_GRP1_EnableClock(LL_AHB2_GRP1_PERIPH_GPIOA);
  /**COMP2 GPIO Configuration
  PA5   ------> COMP2_INM
  PA7   ------> COMP2_INP
  */
  GPIO_InitStruct.Pin = LL_GPIO_PIN_5;
  GPIO_InitStruct.Mode = LL_GPIO_MODE_ANALOG;
  GPIO_InitStruct.Pull = LL_GPIO_PULL_NO;
  LL_GPIO_Init(GPIOA, &GPIO_InitStruct);

  GPIO_InitStruct.Pin = LL_GPIO_PIN_7;
  GPIO_InitStruct.Mode = LL_GPIO_MODE_ANALOG;
  GPIO_InitStruct.Pull = LL_GPIO_PULL_NO;
  LL_GPIO_Init(GPIOA, &GPIO_InitStruct);

  /* COMP2 interrupt Init */
  NVIC_SetPriority(COMP1_2_3_IRQn, NVIC_EncodePriority(NVIC_GetPriorityGrouping(),0, 0));
  NVIC_EnableIRQ(COMP1_2_3_IRQn);

  COMP_InitStruct.InputPlus = LL_COMP_INPUT_PLUS_IO1;
  COMP_InitStruct.InputMinus = LL_COMP_INPUT_MINUS_IO1;
  COMP_InitStruct.InputHysteresis = LL_COMP_HYSTERESIS_70MV;
  COMP_InitStruct.OutputPolarity = LL_COMP_OUTPUTPOL_NONINVERTED;
  COMP_InitStruct.OutputBlankingSource = LL_COMP_BLANKINGSRC_NONE;
  LL_COMP_Init(COMP2, &COMP_InitStruct);

  /* Wait loop initialization and execution */
  /* Note: Variable divided by 2 to compensate partially CPU processing cycles */
  __IO uint32_t wait_loop_index = 0;
  wait_loop_index = (LL_COMP_DELAY_VOLTAGE_SCALER_STAB_US * (SystemCoreClock / (1000000 * 2)));
  while(wait_loop_index != 0)
  {
    wait_loop_index--;
  }
  LL_EXTI_EnableFallingTrig_0_31(LL_EXTI_LINE_22);
  LL_EXTI_EnableRisingTrig_0_31(LL_EXTI_LINE_22);
  LL_EXTI_ClearFlag_0_31(LL_EXTI_LINE_22);
  LL_EXTI_DisableEvent_0_31(LL_EXTI_LINE_22);
  LL_EXTI_EnableIT_0_31(LL_EXTI_LINE_22);

}

static void MX_COMP3_Init(void)
{

  LL_COMP_InitTypeDef COMP_InitStruct = {0};

  LL_GPIO_InitTypeDef GPIO_InitStruct = {0};

  LL_AHB2_GRP1_EnableClock(LL_AHB2_GRP1_PERIPH_GPIOC);
  /**COMP3 GPIO Configuration
  PC0   ------> COMP3_INM
  PC1   ------> COMP3_INP
  */
  GPIO_InitStruct.Pin = LL_GPIO_PIN_0;
  GPIO_InitStruct.Mode = LL_GPIO_MODE_ANALOG;
  GPIO_InitStruct.Pull = LL_GPIO_PULL_NO;
  LL_GPIO_Init(GPIOC, &GPIO_InitStruct);

  GPIO_InitStruct.Pin = LL_GPIO_PIN_1;
  GPIO_InitStruct.Mode = LL_GPIO_MODE_ANALOG;
  GPIO_InitStruct.Pull = LL_GPIO_PULL_NO;
  LL_GPIO_Init(GPIOC, &GPIO_InitStruct);

  /* COMP3 interrupt Init */
  NVIC_SetPriority(COMP1_2_3_IRQn, NVIC_EncodePriority(NVIC_GetPriorityGrouping(),0, 0));
  NVIC_EnableIRQ(COMP1_2_3_IRQn);

  COMP_InitStruct.InputPlus = LL_COMP_INPUT_PLUS_IO2;
  COMP_InitStruct.InputMinus = LL_COMP_INPUT_MINUS_IO2;
  COMP_InitStruct.InputHysteresis = LL_COMP_HYSTERESIS_70MV;
  COMP_InitStruct.OutputPolarity = LL_COMP_OUTPUTPOL_NONINVERTED;
  COMP_InitStruct.OutputBlankingSource = LL_COMP_BLANKINGSRC_NONE;
  LL_COMP_Init(COMP3, &COMP_InitStruct);

  /* Wait loop initialization and execution */
  /* Note: Variable divided by 2 to compensate partially CPU processing cycles */
  __IO uint32_t wait_loop_index = 0;
  wait_loop_index = (LL_COMP_DELAY_VOLTAGE_SCALER_STAB_US * (SystemCoreClock / (1000000 * 2)));
  while(wait_loop_index != 0)
  {
    wait_loop_index--;
  }
  LL_EXTI_EnableFallingTrig_0_31(LL_EXTI_LINE_29);
  LL_EXTI_EnableRisingTrig_0_31(LL_EXTI_LINE_29);
  LL_EXTI_ClearFlag_0_31(LL_EXTI_LINE_29);
  LL_EXTI_DisableEvent_0_31(LL_EXTI_LINE_29);
  LL_EXTI_EnableIT_0_31(LL_EXTI_LINE_29);

}

static void MX_CORDIC_Init(void)
{

  /* Peripheral clock enable */
  LL_AHB1_GRP1_EnableClock(LL_AHB1_GRP1_PERIPH_CORDIC);

  /* nothing else to be configured */

}

static void MX_FDCAN1_Init(void)
{

  hfdcan1.Instance = FDCAN1;
  hfdcan1.Init.ClockDivider = FDCAN_CLOCK_DIV1;
  hfdcan1.Init.FrameFormat = FDCAN_FRAME_CLASSIC;
  hfdcan1.Init.Mode = FDCAN_MODE_NORMAL;
  hfdcan1.Init.AutoRetransmission = DISABLE;
  hfdcan1.Init.TransmitPause = DISABLE;
  hfdcan1.Init.ProtocolException = DISABLE;
  hfdcan1.Init.NominalPrescaler = 16;
  hfdcan1.Init.NominalSyncJumpWidth = 1;
  hfdcan1.Init.NominalTimeSeg1 = 6;
  hfdcan1.Init.NominalTimeSeg2 = 3;
  hfdcan1.Init.DataPrescaler = 1;
  hfdcan1.Init.DataSyncJumpWidth = 1;
  hfdcan1.Init.DataTimeSeg1 = 1;
  hfdcan1.Init.DataTimeSeg2 = 1;
  hfdcan1.Init.StdFiltersNbr = 0;
  hfdcan1.Init.ExtFiltersNbr = 0;
  hfdcan1.Init.TxFifoQueueMode = FDCAN_TX_FIFO_OPERATION;
  if (HAL_FDCAN_Init(&hfdcan1) != HAL_OK)
  {
    Error_Handler();
  }

}

static void MX_FMAC_Init(void)
{

  /* Peripheral clock enable */
  LL_AHB1_GRP1_EnableClock(LL_AHB1_GRP1_PERIPH_FMAC);

  /* FMAC DMA Init */

  /* FMAC_READ Init */
  LL_DMA_SetPeriphRequest(DMA1, LL_DMA_CHANNEL_3, LL_DMAMUX_REQ_FMAC_READ);

  LL_DMA_SetDataTransferDirection(DMA1, LL_DMA_CHANNEL_3, LL_DMA_DIRECTION_PERIPH_TO_MEMORY);

  LL_DMA_SetChannelPriorityLevel(DMA1, LL_DMA_CHANNEL_3, LL_DMA_PRIORITY_LOW);

  LL_DMA_SetMode(DMA1, LL_DMA_CHANNEL_3, LL_DMA_MODE_CIRCULAR);

  LL_DMA_SetPeriphIncMode(DMA1, LL_DMA_CHANNEL_3, LL_DMA_PERIPH_NOINCREMENT);

  LL_DMA_SetMemoryIncMode(DMA1, LL_DMA_CHANNEL_3, LL_DMA_MEMORY_INCREMENT);

  LL_DMA_SetPeriphSize(DMA1, LL_DMA_CHANNEL_3, LL_DMA_PDATAALIGN_WORD);

  LL_DMA_SetMemorySize(DMA1, LL_DMA_CHANNEL_3, LL_DMA_MDATAALIGN_HALFWORD);

  /* FMAC_WRITE Init */
  LL_DMA_SetPeriphRequest(DMA1, LL_DMA_CHANNEL_2, LL_DMAMUX_REQ_FMAC_WRITE);

  LL_DMA_SetDataTransferDirection(DMA1, LL_DMA_CHANNEL_2, LL_DMA_DIRECTION_MEMORY_TO_PERIPH);

  LL_DMA_SetChannelPriorityLevel(DMA1, LL_DMA_CHANNEL_2, LL_DMA_PRIORITY_LOW);

  LL_DMA_SetMode(DMA1, LL_DMA_CHANNEL_2, LL_DMA_MODE_NORMAL);

  LL_DMA_SetPeriphIncMode(DMA1, LL_DMA_CHANNEL_2, LL_DMA_PERIPH_NOINCREMENT);

  LL_DMA_SetMemoryIncMode(DMA1, LL_DMA_CHANNEL_2, LL_DMA_MEMORY_INCREMENT);

  LL_DMA_SetPeriphSize(DMA1, LL_DMA_CHANNEL_2, LL_DMA_PDATAALIGN_WORD);

  LL_DMA_SetMemorySize(DMA1, LL_DMA_CHANNEL_2, LL_DMA_MDATAALIGN_HALFWORD);

  /* nothing to be configured */

}

static void MX_I2C3_Init(void)
{

  LL_I2C_InitTypeDef I2C_InitStruct = {0};

  LL_GPIO_InitTypeDef GPIO_InitStruct = {0};

  LL_RCC_SetI2CClockSource(LL_RCC_I2C3_CLKSOURCE_PCLK1);

  LL_AHB2_GRP1_EnableClock(LL_AHB2_GRP1_PERIPH_GPIOC);
  /**I2C3 GPIO Configuration
  PC8   ------> I2C3_SCL
  PC9   ------> I2C3_SDA
  */
  GPIO_InitStruct.Pin = LL_GPIO_PIN_8;
  GPIO_InitStruct.Mode = LL_GPIO_MODE_ALTERNATE;
  GPIO_InitStruct.Speed = LL_GPIO_SPEED_FREQ_LOW;
  GPIO_InitStruct.OutputType = LL_GPIO_OUTPUT_OPENDRAIN;
  GPIO_InitStruct.Pull = LL_GPIO_PULL_NO;
  GPIO_InitStruct.Alternate = LL_GPIO_AF_8;
  LL_GPIO_Init(GPIOC, &GPIO_InitStruct);

  GPIO_InitStruct.Pin = LL_GPIO_PIN_9;
  GPIO_InitStruct.Mode = LL_GPIO_MODE_ALTERNATE;
  GPIO_InitStruct.Speed = LL_GPIO_SPEED_FREQ_LOW;
  GPIO_InitStruct.OutputType = LL_GPIO_OUTPUT_OPENDRAIN;
  GPIO_InitStruct.Pull = LL_GPIO_PULL_NO;
  GPIO_InitStruct.Alternate = LL_GPIO_AF_8;
  LL_GPIO_Init(GPIOC, &GPIO_InitStruct);

  /* Peripheral clock enable */
  LL_APB1_GRP1_EnableClock(LL_APB1_GRP1_PERIPH_I2C3);

  /** I2C Initialization
  */
  I2C_InitStruct.PeripheralMode = LL_I2C_MODE_I2C;
  I2C_InitStruct.Timing = 0x30D29DE4;
  I2C_InitStruct.AnalogFilter = LL_I2C_ANALOGFILTER_ENABLE;
  I2C_InitStruct.DigitalFilter = 0;
  I2C_InitStruct.OwnAddress1 = 0;
  I2C_InitStruct.TypeAcknowledge = LL_I2C_ACK;
  I2C_InitStruct.OwnAddrSize = LL_I2C_OWNADDRESS1_7BIT;
  LL_I2C_Init(I2C3, &I2C_InitStruct);
  LL_I2C_EnableAutoEndMode(I2C3);
  LL_I2C_SetOwnAddress2(I2C3, 0, LL_I2C_OWNADDRESS2_NOMASK);
  LL_I2C_DisableOwnAddress2(I2C3);
  LL_I2C_DisableGeneralCall(I2C3);
  LL_I2C_EnableClockStretching(I2C3);

}

static void MX_OPAMP2_Init(void)
{

  LL_OPAMP_InitTypeDef OPAMP_InitStruct = {0};

  LL_GPIO_InitTypeDef GPIO_InitStruct = {0};

  LL_AHB2_GRP1_EnableClock(LL_AHB2_GRP1_PERIPH_GPIOB);
  /**OPAMP2 GPIO Configuration
  PB0   ------> OPAMP2_VINP
  */
  GPIO_InitStruct.Pin = LL_GPIO_PIN_0;
  GPIO_InitStruct.Mode = LL_GPIO_MODE_ANALOG;
  GPIO_InitStruct.Pull = LL_GPIO_PULL_NO;
  LL_GPIO_Init(GPIOB, &GPIO_InitStruct);

  OPAMP_InitStruct.PowerMode = LL_OPAMP_POWERMODE_NORMALSPEED;
  OPAMP_InitStruct.FunctionalMode = LL_OPAMP_MODE_FOLLOWER;
  OPAMP_InitStruct.InputNonInverting = LL_OPAMP_INPUT_NONINVERT_IO2;
  LL_OPAMP_Init(OPAMP2, &OPAMP_InitStruct);
  LL_OPAMP_SetInputsMuxMode(OPAMP2, LL_OPAMP_INPUT_MUX_DISABLE);
  LL_OPAMP_SetInternalOutput(OPAMP2, LL_OPAMP_INTERNAL_OUPUT_ENABLED);
  LL_OPAMP_SetTrimmingMode(OPAMP2, LL_OPAMP_TRIMMING_FACTORY);

}

static void MX_OPAMP3_Init(void)
{

  LL_OPAMP_InitTypeDef OPAMP_InitStruct = {0};

  LL_GPIO_InitTypeDef GPIO_InitStruct = {0};

  LL_AHB2_GRP1_EnableClock(LL_AHB2_GRP1_PERIPH_GPIOA);
  /**OPAMP3 GPIO Configuration
  PA1   ------> OPAMP3_VINP
  */
  GPIO_InitStruct.Pin = LL_GPIO_PIN_1;
  GPIO_InitStruct.Mode = LL_GPIO_MODE_ANALOG;
  GPIO_InitStruct.Pull = LL_GPIO_PULL_NO;
  LL_GPIO_Init(GPIOA, &GPIO_InitStruct);

  OPAMP_InitStruct.PowerMode = LL_OPAMP_POWERMODE_NORMALSPEED;
  OPAMP_InitStruct.FunctionalMode = LL_OPAMP_MODE_PGA;
  OPAMP_InitStruct.InputNonInverting = LL_OPAMP_INPUT_NONINVERT_IO2;
  OPAMP_InitStruct.InputInverting = LL_OPAMP_INPUT_INVERT_CONNECT_NO;
  LL_OPAMP_Init(OPAMP3, &OPAMP_InitStruct);
  LL_OPAMP_SetInputsMuxMode(OPAMP3, LL_OPAMP_INPUT_MUX_DISABLE);
  LL_OPAMP_SetInternalOutput(OPAMP3, LL_OPAMP_INTERNAL_OUPUT_ENABLED);
  LL_OPAMP_SetPGAGain(OPAMP3, LL_OPAMP_PGA_GAIN_2_OR_MINUS_1);
  LL_OPAMP_SetTrimmingMode(OPAMP3, LL_OPAMP_TRIMMING_FACTORY);

}

static void MX_TIM1_Init(void)
{

  LL_TIM_InitTypeDef TIM_InitStruct = {0};
  LL_TIM_OC_InitTypeDef TIM_OC_InitStruct = {0};
  LL_TIM_BDTR_InitTypeDef TIM_BDTRInitStruct = {0};

  LL_GPIO_InitTypeDef GPIO_InitStruct = {0};

  /* Peripheral clock enable */
  LL_APB2_GRP1_EnableClock(LL_APB2_GRP1_PERIPH_TIM1);

  /* TIM1 interrupt Init */
  NVIC_SetPriority(TIM1_UP_TIM16_IRQn, NVIC_EncodePriority(NVIC_GetPriorityGrouping(),0, 0));
  NVIC_EnableIRQ(TIM1_UP_TIM16_IRQn);

  TIM_InitStruct.Prescaler = 4;
  TIM_InitStruct.CounterMode = LL_TIM_COUNTERMODE_UP;
  TIM_InitStruct.Autoreload = 999;
  TIM_InitStruct.ClockDivision = LL_TIM_CLOCKDIVISION_DIV1;
  TIM_InitStruct.RepetitionCounter = 0;
  LL_TIM_Init(TIM1, &TIM_InitStruct);
  LL_TIM_DisableARRPreload(TIM1);
  LL_TIM_OC_EnablePreload(TIM1, LL_TIM_CHANNEL_CH1);
  TIM_OC_InitStruct.OCMode = LL_TIM_OCMODE_PWM1;
  TIM_OC_InitStruct.OCState = LL_TIM_OCSTATE_DISABLE;
  TIM_OC_InitStruct.OCNState = LL_TIM_OCSTATE_DISABLE;
  TIM_OC_InitStruct.CompareValue = 0;
  TIM_OC_InitStruct.OCPolarity = LL_TIM_OCPOLARITY_HIGH;
  TIM_OC_InitStruct.OCNPolarity = LL_TIM_OCPOLARITY_HIGH;
  TIM_OC_InitStruct.OCIdleState = LL_TIM_OCIDLESTATE_LOW;
  TIM_OC_InitStruct.OCNIdleState = LL_TIM_OCIDLESTATE_LOW;
  LL_TIM_OC_Init(TIM1, LL_TIM_CHANNEL_CH1, &TIM_OC_InitStruct);
  LL_TIM_OC_DisableFast(TIM1, LL_TIM_CHANNEL_CH1);
  LL_TIM_OC_EnablePreload(TIM1, LL_TIM_CHANNEL_CH2);
  LL_TIM_OC_Init(TIM1, LL_TIM_CHANNEL_CH2, &TIM_OC_InitStruct);
  LL_TIM_OC_DisableFast(TIM1, LL_TIM_CHANNEL_CH2);
  LL_TIM_OC_EnablePreload(TIM1, LL_TIM_CHANNEL_CH3);
  LL_TIM_OC_Init(TIM1, LL_TIM_CHANNEL_CH3, &TIM_OC_InitStruct);
  LL_TIM_OC_DisableFast(TIM1, LL_TIM_CHANNEL_CH3);
  LL_TIM_SetTriggerOutput(TIM1, LL_TIM_TRGO_RESET);
  LL_TIM_SetTriggerOutput2(TIM1, LL_TIM_TRGO2_RESET);
  LL_TIM_DisableMasterSlaveMode(TIM1);
  TIM_BDTRInitStruct.OSSRState = LL_TIM_OSSR_DISABLE;
  TIM_BDTRInitStruct.OSSIState = LL_TIM_OSSI_DISABLE;
  TIM_BDTRInitStruct.LockLevel = LL_TIM_LOCKLEVEL_OFF;
  TIM_BDTRInitStruct.DeadTime = 128;
  TIM_BDTRInitStruct.BreakState = LL_TIM_BREAK_DISABLE;
  TIM_BDTRInitStruct.BreakPolarity = LL_TIM_BREAK_POLARITY_HIGH;
  TIM_BDTRInitStruct.BreakFilter = LL_TIM_BREAK_FILTER_FDIV1;
  TIM_BDTRInitStruct.BreakAFMode = LL_TIM_BREAK_AFMODE_INPUT;
  TIM_BDTRInitStruct.Break2State = LL_TIM_BREAK2_DISABLE;
  TIM_BDTRInitStruct.Break2Polarity = LL_TIM_BREAK2_POLARITY_HIGH;
  TIM_BDTRInitStruct.Break2Filter = LL_TIM_BREAK2_FILTER_FDIV1;
  TIM_BDTRInitStruct.Break2AFMode = LL_TIM_BREAK_AFMODE_INPUT;
  TIM_BDTRInitStruct.AutomaticOutput = LL_TIM_AUTOMATICOUTPUT_DISABLE;
  LL_TIM_BDTR_Init(TIM1, &TIM_BDTRInitStruct);
  LL_AHB2_GRP1_EnableClock(LL_AHB2_GRP1_PERIPH_GPIOE);
  /**TIM1 GPIO Configuration
  PE8   ------> TIM1_CH1N
  PE9   ------> TIM1_CH1
  PE10   ------> TIM1_CH2N
  PE11   ------> TIM1_CH2
  PE12   ------> TIM1_CH3N
  PE13   ------> TIM1_CH3
  */
  GPIO_InitStruct.Pin = LL_GPIO_PIN_8;
  GPIO_InitStruct.Mode = LL_GPIO_MODE_ALTERNATE;
  GPIO_InitStruct.Speed = LL_GPIO_SPEED_FREQ_LOW;
  GPIO_InitStruct.OutputType = LL_GPIO_OUTPUT_PUSHPULL;
  GPIO_InitStruct.Pull = LL_GPIO_PULL_NO;
  GPIO_InitStruct.Alternate = LL_GPIO_AF_2;
  LL_GPIO_Init(GPIOE, &GPIO_InitStruct);

  GPIO_InitStruct.Pin = LL_GPIO_PIN_9;
  GPIO_InitStruct.Mode = LL_GPIO_MODE_ALTERNATE;
  GPIO_InitStruct.Speed = LL_GPIO_SPEED_FREQ_LOW;
  GPIO_InitStruct.OutputType = LL_GPIO_OUTPUT_PUSHPULL;
  GPIO_InitStruct.Pull = LL_GPIO_PULL_NO;
  GPIO_InitStruct.Alternate = LL_GPIO_AF_2;
  LL_GPIO_Init(GPIOE, &GPIO_InitStruct);

  GPIO_InitStruct.Pin = LL_GPIO_PIN_10;
  GPIO_InitStruct.Mode = LL_GPIO_MODE_ALTERNATE;
  GPIO_InitStruct.Speed = LL_GPIO_SPEED_FREQ_LOW;
  GPIO_InitStruct.OutputType = LL_GPIO_OUTPUT_PUSHPULL;
  GPIO_InitStruct.Pull = LL_GPIO_PULL_NO;
  GPIO_InitStruct.Alternate = LL_GPIO_AF_2;
  LL_GPIO_Init(GPIOE, &GPIO_InitStruct);

  GPIO_InitStruct.Pin = LL_GPIO_PIN_11;
  GPIO_InitStruct.Mode = LL_GPIO_MODE_ALTERNATE;
  GPIO_InitStruct.Speed = LL_GPIO_SPEED_FREQ_LOW;
  GPIO_InitStruct.OutputType = LL_GPIO_OUTPUT_PUSHPULL;
  GPIO_InitStruct.Pull = LL_GPIO_PULL_NO;
  GPIO_InitStruct.Alternate = LL_GPIO_AF_2;
  LL_GPIO_Init(GPIOE, &GPIO_InitStruct);

  GPIO_InitStruct.Pin = LL_GPIO_PIN_12;
  GPIO_InitStruct.Mode = LL_GPIO_MODE_ALTERNATE;
  GPIO_InitStruct.Speed = LL_GPIO_SPEED_FREQ_LOW;
  GPIO_InitStruct.OutputType = LL_GPIO_OUTPUT_PUSHPULL;
  GPIO_InitStruct.Pull = LL_GPIO_PULL_NO;
  GPIO_InitStruct.Alternate = LL_GPIO_AF_2;
  LL_GPIO_Init(GPIOE, &GPIO_InitStruct);

  GPIO_InitStruct.Pin = LL_GPIO_PIN_13;
  GPIO_InitStruct.Mode = LL_GPIO_MODE_ALTERNATE;
  GPIO_InitStruct.Speed = LL_GPIO_SPEED_FREQ_LOW;
  GPIO_InitStruct.OutputType = LL_GPIO_OUTPUT_PUSHPULL;
  GPIO_InitStruct.Pull = LL_GPIO_PULL_NO;
  GPIO_InitStruct.Alternate = LL_GPIO_AF_2;
  LL_GPIO_Init(GPIOE, &GPIO_InitStruct);

}

static void MX_TIM3_Init(void)
{

  LL_TIM_InitTypeDef TIM_InitStruct = {0};

  LL_GPIO_InitTypeDef GPIO_InitStruct = {0};

  /* Peripheral clock enable */
  LL_APB1_GRP1_EnableClock(LL_APB1_GRP1_PERIPH_TIM3);

  LL_AHB2_GRP1_EnableClock(LL_AHB2_GRP1_PERIPH_GPIOB);
  /**TIM3 GPIO Configuration
  PB4   ------> TIM3_CH1
  PB5   ------> TIM3_CH2
  */
  GPIO_InitStruct.Pin = LL_GPIO_PIN_4;
  GPIO_InitStruct.Mode = LL_GPIO_MODE_ALTERNATE;
  GPIO_InitStruct.Speed = LL_GPIO_SPEED_FREQ_LOW;
  GPIO_InitStruct.OutputType = LL_GPIO_OUTPUT_PUSHPULL;
  GPIO_InitStruct.Pull = LL_GPIO_PULL_NO;
  GPIO_InitStruct.Alternate = LL_GPIO_AF_2;
  LL_GPIO_Init(GPIOB, &GPIO_InitStruct);

  GPIO_InitStruct.Pin = LL_GPIO_PIN_5;
  GPIO_InitStruct.Mode = LL_GPIO_MODE_ALTERNATE;
  GPIO_InitStruct.Speed = LL_GPIO_SPEED_FREQ_LOW;
  GPIO_InitStruct.OutputType = LL_GPIO_OUTPUT_PUSHPULL;
  GPIO_InitStruct.Pull = LL_GPIO_PULL_NO;
  GPIO_InitStruct.Alternate = LL_GPIO_AF_2;
  LL_GPIO_Init(GPIOB, &GPIO_InitStruct);

  TIM_InitStruct.Prescaler = 4;
  TIM_InitStruct.CounterMode = LL_TIM_COUNTERMODE_UP;
  TIM_InitStruct.Autoreload = 999;
  TIM_InitStruct.ClockDivision = LL_TIM_CLOCKDIVISION_DIV1;
  LL_TIM_Init(TIM3, &TIM_InitStruct);
  LL_TIM_DisableARRPreload(TIM3);
  LL_TIM_SetTriggerOutput(TIM3, LL_TIM_TRGO_RESET);
  LL_TIM_DisableMasterSlaveMode(TIM3);
  LL_TIM_IC_SetActiveInput(TIM3, LL_TIM_CHANNEL_CH1, LL_TIM_ACTIVEINPUT_DIRECTTI);
  LL_TIM_IC_SetPrescaler(TIM3, LL_TIM_CHANNEL_CH1, LL_TIM_ICPSC_DIV1);
  LL_TIM_IC_SetFilter(TIM3, LL_TIM_CHANNEL_CH1, LL_TIM_IC_FILTER_FDIV1);
  LL_TIM_IC_SetPolarity(TIM3, LL_TIM_CHANNEL_CH1, LL_TIM_IC_POLARITY_RISING);
  LL_TIM_IC_SetActiveInput(TIM3, LL_TIM_CHANNEL_CH2, LL_TIM_ACTIVEINPUT_DIRECTTI);
  LL_TIM_IC_SetPrescaler(TIM3, LL_TIM_CHANNEL_CH2, LL_TIM_ICPSC_DIV1);
  LL_TIM_IC_SetFilter(TIM3, LL_TIM_CHANNEL_CH2, LL_TIM_IC_FILTER_FDIV1);
  LL_TIM_IC_SetPolarity(TIM3, LL_TIM_CHANNEL_CH2, LL_TIM_IC_POLARITY_RISING);

}

static void MX_TIM6_Init(void)
{

  LL_TIM_InitTypeDef TIM_InitStruct = {0};

  /* Peripheral clock enable */
  LL_APB1_GRP1_EnableClock(LL_APB1_GRP1_PERIPH_TIM6);

  /* TIM6 interrupt Init */
  NVIC_SetPriority(TIM6_DAC_IRQn, NVIC_EncodePriority(NVIC_GetPriorityGrouping(),0, 0));
  NVIC_EnableIRQ(TIM6_DAC_IRQn);

  TIM_InitStruct.Prescaler = 4;
  TIM_InitStruct.CounterMode = LL_TIM_COUNTERMODE_UP;
  TIM_InitStruct.Autoreload = 999;
  LL_TIM_Init(TIM6, &TIM_InitStruct);
  LL_TIM_DisableARRPreload(TIM6);
  LL_TIM_SetTriggerOutput(TIM6, LL_TIM_TRGO_RESET);
  LL_TIM_DisableMasterSlaveMode(TIM6);

}

static void MX_USART1_UART_Init(void)
{

  LL_USART_InitTypeDef USART_InitStruct = {0};

  LL_GPIO_InitTypeDef GPIO_InitStruct = {0};

  LL_RCC_SetUSARTClockSource(LL_RCC_USART1_CLKSOURCE_PCLK2);

  /* Peripheral clock enable */
  LL_APB2_GRP1_EnableClock(LL_APB2_GRP1_PERIPH_USART1);

  LL_AHB2_GRP1_EnableClock(LL_AHB2_GRP1_PERIPH_GPIOA);
  /**USART1 GPIO Configuration
  PA9   ------> USART1_TX
  PA10   ------> USART1_RX
  */
  GPIO_InitStruct.Pin = LL_GPIO_PIN_9;
  GPIO_InitStruct.Mode = LL_GPIO_MODE_ALTERNATE;
  GPIO_InitStruct.Speed = LL_GPIO_SPEED_FREQ_LOW;
  GPIO_InitStruct.OutputType = LL_GPIO_OUTPUT_PUSHPULL;
  GPIO_InitStruct.Pull = LL_GPIO_PULL_NO;
  GPIO_InitStruct.Alternate = LL_GPIO_AF_7;
  LL_GPIO_Init(GPIOA, &GPIO_InitStruct);

  GPIO_InitStruct.Pin = LL_GPIO_PIN_10;
  GPIO_InitStruct.Mode = LL_GPIO_MODE_ALTERNATE;
  GPIO_InitStruct.Speed = LL_GPIO_SPEED_FREQ_LOW;
  GPIO_InitStruct.OutputType = LL_GPIO_OUTPUT_PUSHPULL;
  GPIO_InitStruct.Pull = LL_GPIO_PULL_NO;
  GPIO_InitStruct.Alternate = LL_GPIO_AF_7;
  LL_GPIO_Init(GPIOA, &GPIO_InitStruct);

  USART_InitStruct.PrescalerValue = LL_USART_PRESCALER_DIV1;
  USART_InitStruct.BaudRate = 115200;
  USART_InitStruct.DataWidth = LL_USART_DATAWIDTH_8B;
  USART_InitStruct.StopBits = LL_USART_STOPBITS_1;
  USART_InitStruct.Parity = LL_USART_PARITY_NONE;
  USART_InitStruct.TransferDirection = LL_USART_DIRECTION_TX_RX;
  USART_InitStruct.HardwareFlowControl = LL_USART_HWCONTROL_NONE;
  USART_InitStruct.OverSampling = LL_USART_OVERSAMPLING_16;
  LL_USART_Init(USART1, &USART_InitStruct);
  LL_USART_SetTXFIFOThreshold(USART1, LL_USART_FIFOTHRESHOLD_1_8);
  LL_USART_SetRXFIFOThreshold(USART1, LL_USART_FIFOTHRESHOLD_1_8);
  LL_USART_DisableFIFO(USART1);
  LL_USART_ConfigAsyncMode(USART1);

  LL_USART_Enable(USART1);

  /* Polling USART1 initialisation */
  while((!(LL_USART_IsActiveFlag_TEACK(USART1))) || (!(LL_USART_IsActiveFlag_REACK(USART1))))
  {
  }

}

static void MX_DMA_Init(void)
{

  /* Init with LL driver */
  /* DMA controller clock enable */
  LL_AHB1_GRP1_EnableClock(LL_AHB1_GRP1_PERIPH_DMAMUX1);
  LL_AHB1_GRP1_EnableClock(LL_AHB1_GRP1_PERIPH_DMA1);

}

static void MX_GPIO_Init(void)
{
  LL_GPIO_InitTypeDef GPIO_InitStruct = {0};

  /* GPIO Ports Clock Enable */
  LL_AHB2_GRP1_EnableClock(LL_AHB2_GRP1_PERIPH_GPIOE);
  LL_AHB2_GRP1_EnableClock(LL_AHB2_GRP1_PERIPH_GPIOF);
  LL_AHB2_GRP1_EnableClock(LL_AHB2_GRP1_PERIPH_GPIOG);
  LL_AHB2_GRP1_EnableClock(LL_AHB2_GRP1_PERIPH_GPIOC);
  LL_AHB2_GRP1_EnableClock(LL_AHB2_GRP1_PERIPH_GPIOA);
  LL_AHB2_GRP1_EnableClock(LL_AHB2_GRP1_PERIPH_GPIOB);
  LL_AHB2_GRP1_EnableClock(LL_AHB2_GRP1_PERIPH_GPIOD);

  /**/
  LL_GPIO_ResetOutputPin(LD_ID_GPIO_Port, LD_ID_Pin);

  /**/
  LL_GPIO_ResetOutputPin(LD_STATUS_GPIO_Port, LD_STATUS_Pin);

  /**/
  GPIO_InitStruct.Pin = LL_GPIO_PIN_2;
  GPIO_InitStruct.Mode = LL_GPIO_MODE_INPUT;
  GPIO_InitStruct.Pull = LL_GPIO_PULL_NO;
  LL_GPIO_Init(GPIOE, &GPIO_InitStruct);

  /**/
  GPIO_InitStruct.Pin = LL_GPIO_PIN_3;
  GPIO_InitStruct.Mode = LL_GPIO_MODE_INPUT;
  GPIO_InitStruct.Pull = LL_GPIO_PULL_NO;
  LL_GPIO_Init(GPIOE, &GPIO_InitStruct);

  /**/
  GPIO_InitStruct.Pin = LL_GPIO_PIN_4;
  GPIO_InitStruct.Mode = LL_GPIO_MODE_INPUT;
  GPIO_InitStruct.Pull = LL_GPIO_PULL_NO;
  LL_GPIO_Init(GPIOE, &GPIO_InitStruct);

  /**/
  GPIO_InitStruct.Pin = LL_GPIO_PIN_5;
  GPIO_InitStruct.Mode = LL_GPIO_MODE_INPUT;
  GPIO_InitStruct.Pull = LL_GPIO_PULL_NO;
  LL_GPIO_Init(GPIOE, &GPIO_InitStruct);

  /**/
  GPIO_InitStruct.Pin = LL_GPIO_PIN_6;
  GPIO_InitStruct.Mode = LL_GPIO_MODE_INPUT;
  GPIO_InitStruct.Pull = LL_GPIO_PULL_NO;
  LL_GPIO_Init(GPIOE, &GPIO_InitStruct);

  /**/
  GPIO_InitStruct.Pin = LL_GPIO_PIN_9;
  GPIO_InitStruct.Mode = LL_GPIO_MODE_INPUT;
  GPIO_InitStruct.Pull = LL_GPIO_PULL_NO;
  LL_GPIO_Init(GPIOF, &GPIO_InitStruct);

  /**/
  GPIO_InitStruct.Pin = LL_GPIO_PIN_10;
  GPIO_InitStruct.Mode = LL_GPIO_MODE_INPUT;
  GPIO_InitStruct.Pull = LL_GPIO_PULL_NO;
  LL_GPIO_Init(GPIOF, &GPIO_InitStruct);

  /**/
  GPIO_InitStruct.Pin = LL_GPIO_PIN_10;
  GPIO_InitStruct.Mode = LL_GPIO_MODE_INPUT;
  GPIO_InitStruct.Pull = LL_GPIO_PULL_NO;
  LL_GPIO_Init(GPIOG, &GPIO_InitStruct);

  /**/
  GPIO_InitStruct.Pin = LL_GPIO_PIN_2;
  GPIO_InitStruct.Mode = LL_GPIO_MODE_INPUT;
  GPIO_InitStruct.Pull = LL_GPIO_PULL_NO;
  LL_GPIO_Init(GPIOF, &GPIO_InitStruct);

  /**/
  GPIO_InitStruct.Pin = LL_GPIO_PIN_7;
  GPIO_InitStruct.Mode = LL_GPIO_MODE_INPUT;
  GPIO_InitStruct.Pull = LL_GPIO_PULL_NO;
  LL_GPIO_Init(GPIOE, &GPIO_InitStruct);

  /**/
  GPIO_InitStruct.Pin = LL_GPIO_PIN_11;
  GPIO_InitStruct.Mode = LL_GPIO_MODE_INPUT;
  GPIO_InitStruct.Pull = LL_GPIO_PULL_NO;
  LL_GPIO_Init(GPIOB, &GPIO_InitStruct);

  /**/
  GPIO_InitStruct.Pin = LL_GPIO_PIN_12;
  GPIO_InitStruct.Mode = LL_GPIO_MODE_INPUT;
  GPIO_InitStruct.Pull = LL_GPIO_PULL_NO;
  LL_GPIO_Init(GPIOB, &GPIO_InitStruct);

  /**/
  GPIO_InitStruct.Pin = LL_GPIO_PIN_13;
  GPIO_InitStruct.Mode = LL_GPIO_MODE_INPUT;
  GPIO_InitStruct.Pull = LL_GPIO_PULL_NO;
  LL_GPIO_Init(GPIOB, &GPIO_InitStruct);

  /**/
  GPIO_InitStruct.Pin = LL_GPIO_PIN_14;
  GPIO_InitStruct.Mode = LL_GPIO_MODE_INPUT;
  GPIO_InitStruct.Pull = LL_GPIO_PULL_NO;
  LL_GPIO_Init(GPIOB, &GPIO_InitStruct);

  /**/
  GPIO_InitStruct.Pin = LL_GPIO_PIN_15;
  GPIO_InitStruct.Mode = LL_GPIO_MODE_INPUT;
  GPIO_InitStruct.Pull = LL_GPIO_PULL_NO;
  LL_GPIO_Init(GPIOB, &GPIO_InitStruct);

  /**/
  GPIO_InitStruct.Pin = LL_GPIO_PIN_8;
  GPIO_InitStruct.Mode = LL_GPIO_MODE_INPUT;
  GPIO_InitStruct.Pull = LL_GPIO_PULL_NO;
  LL_GPIO_Init(GPIOD, &GPIO_InitStruct);

  /**/
  GPIO_InitStruct.Pin = LL_GPIO_PIN_9;
  GPIO_InitStruct.Mode = LL_GPIO_MODE_INPUT;
  GPIO_InitStruct.Pull = LL_GPIO_PULL_NO;
  LL_GPIO_Init(GPIOD, &GPIO_InitStruct);

  /**/
  GPIO_InitStruct.Pin = LL_GPIO_PIN_10;
  GPIO_InitStruct.Mode = LL_GPIO_MODE_INPUT;
  GPIO_InitStruct.Pull = LL_GPIO_PULL_NO;
  LL_GPIO_Init(GPIOD, &GPIO_InitStruct);

  /**/
  GPIO_InitStruct.Pin = LL_GPIO_PIN_11;
  GPIO_InitStruct.Mode = LL_GPIO_MODE_INPUT;
  GPIO_InitStruct.Pull = LL_GPIO_PULL_NO;
  LL_GPIO_Init(GPIOD, &GPIO_InitStruct);

  /**/
  GPIO_InitStruct.Pin = LL_GPIO_PIN_12;
  GPIO_InitStruct.Mode = LL_GPIO_MODE_INPUT;
  GPIO_InitStruct.Pull = LL_GPIO_PULL_NO;
  LL_GPIO_Init(GPIOD, &GPIO_InitStruct);

  /**/
  GPIO_InitStruct.Pin = LL_GPIO_PIN_13;
  GPIO_InitStruct.Mode = LL_GPIO_MODE_INPUT;
  GPIO_InitStruct.Pull = LL_GPIO_PULL_NO;
  LL_GPIO_Init(GPIOD, &GPIO_InitStruct);

  /**/
  GPIO_InitStruct.Pin = LL_GPIO_PIN_14;
  GPIO_InitStruct.Mode = LL_GPIO_MODE_INPUT;
  GPIO_InitStruct.Pull = LL_GPIO_PULL_NO;
  LL_GPIO_Init(GPIOD, &GPIO_InitStruct);

  /**/
  GPIO_InitStruct.Pin = LL_GPIO_PIN_15;
  GPIO_InitStruct.Mode = LL_GPIO_MODE_INPUT;
  GPIO_InitStruct.Pull = LL_GPIO_PULL_NO;
  LL_GPIO_Init(GPIOD, &GPIO_InitStruct);

  /**/
  GPIO_InitStruct.Pin = LL_GPIO_PIN_6;
  GPIO_InitStruct.Mode = LL_GPIO_MODE_INPUT;
  GPIO_InitStruct.Pull = LL_GPIO_PULL_NO;
  LL_GPIO_Init(GPIOC, &GPIO_InitStruct);

  /**/
  GPIO_InitStruct.Pin = LL_GPIO_PIN_7;
  GPIO_InitStruct.Mode = LL_GPIO_MODE_INPUT;
  GPIO_InitStruct.Pull = LL_GPIO_PULL_NO;
  LL_GPIO_Init(GPIOC, &GPIO_InitStruct);

  /**/
  GPIO_InitStruct.Pin = LD_ID_Pin;
  GPIO_InitStruct.Mode = LL_GPIO_MODE_OUTPUT;
  GPIO_InitStruct.Speed = LL_GPIO_SPEED_FREQ_LOW;
  GPIO_InitStruct.OutputType = LL_GPIO_OUTPUT_PUSHPULL;
  GPIO_InitStruct.Pull = LL_GPIO_PULL_NO;
  LL_GPIO_Init(LD_ID_GPIO_Port, &GPIO_InitStruct);

  /**/
  GPIO_InitStruct.Pin = LL_GPIO_PIN_10;
  GPIO_InitStruct.Mode = LL_GPIO_MODE_INPUT;
  GPIO_InitStruct.Pull = LL_GPIO_PULL_NO;
  LL_GPIO_Init(GPIOC, &GPIO_InitStruct);

  /**/
  GPIO_InitStruct.Pin = LL_GPIO_PIN_11;
  GPIO_InitStruct.Mode = LL_GPIO_MODE_INPUT;
  GPIO_InitStruct.Pull = LL_GPIO_PULL_NO;
  LL_GPIO_Init(GPIOC, &GPIO_InitStruct);

  /**/
  GPIO_InitStruct.Pin = LL_GPIO_PIN_12;
  GPIO_InitStruct.Mode = LL_GPIO_MODE_INPUT;
  GPIO_InitStruct.Pull = LL_GPIO_PULL_NO;
  LL_GPIO_Init(GPIOC, &GPIO_InitStruct);

  /**/
  GPIO_InitStruct.Pin = LL_GPIO_PIN_0;
  GPIO_InitStruct.Mode = LL_GPIO_MODE_INPUT;
  GPIO_InitStruct.Pull = LL_GPIO_PULL_NO;
  LL_GPIO_Init(GPIOD, &GPIO_InitStruct);

  /**/
  GPIO_InitStruct.Pin = LL_GPIO_PIN_1;
  GPIO_InitStruct.Mode = LL_GPIO_MODE_INPUT;
  GPIO_InitStruct.Pull = LL_GPIO_PULL_NO;
  LL_GPIO_Init(GPIOD, &GPIO_InitStruct);

  /**/
  GPIO_InitStruct.Pin = LD_STATUS_Pin;
  GPIO_InitStruct.Mode = LL_GPIO_MODE_OUTPUT;
  GPIO_InitStruct.Speed = LL_GPIO_SPEED_FREQ_LOW;
  GPIO_InitStruct.OutputType = LL_GPIO_OUTPUT_PUSHPULL;
  GPIO_InitStruct.Pull = LL_GPIO_PULL_NO;
  LL_GPIO_Init(LD_STATUS_GPIO_Port, &GPIO_InitStruct);

  /**/
  GPIO_InitStruct.Pin = LL_GPIO_PIN_3;
  GPIO_InitStruct.Mode = LL_GPIO_MODE_INPUT;
  GPIO_InitStruct.Pull = LL_GPIO_PULL_NO;
  LL_GPIO_Init(GPIOD, &GPIO_InitStruct);

  /**/
  GPIO_InitStruct.Pin = LL_GPIO_PIN_4;
  GPIO_InitStruct.Mode = LL_GPIO_MODE_INPUT;
  GPIO_InitStruct.Pull = LL_GPIO_PULL_NO;
  LL_GPIO_Init(GPIOD, &GPIO_InitStruct);

  /**/
  GPIO_InitStruct.Pin = LL_GPIO_PIN_5;
  GPIO_InitStruct.Mode = LL_GPIO_MODE_INPUT;
  GPIO_InitStruct.Pull = LL_GPIO_PULL_NO;
  LL_GPIO_Init(GPIOD, &GPIO_InitStruct);

  /**/
  GPIO_InitStruct.Pin = LL_GPIO_PIN_6;
  GPIO_InitStruct.Mode = LL_GPIO_MODE_INPUT;
  GPIO_InitStruct.Pull = LL_GPIO_PULL_NO;
  LL_GPIO_Init(GPIOD, &GPIO_InitStruct);

  /**/
  GPIO_InitStruct.Pin = LL_GPIO_PIN_7;
  GPIO_InitStruct.Mode = LL_GPIO_MODE_INPUT;
  GPIO_InitStruct.Pull = LL_GPIO_PULL_NO;
  LL_GPIO_Init(GPIOD, &GPIO_InitStruct);

  /**/
  GPIO_InitStruct.Pin = LL_GPIO_PIN_8;
  GPIO_InitStruct.Mode = LL_GPIO_MODE_INPUT;
  GPIO_InitStruct.Pull = LL_GPIO_PULL_NO;
  LL_GPIO_Init(GPIOB, &GPIO_InitStruct);

  /**/
  GPIO_InitStruct.Pin = LL_GPIO_PIN_0;
  GPIO_InitStruct.Mode = LL_GPIO_MODE_INPUT;
  GPIO_InitStruct.Pull = LL_GPIO_PULL_NO;
  LL_GPIO_Init(GPIOE, &GPIO_InitStruct);

  /**/
  GPIO_InitStruct.Pin = LL_GPIO_PIN_1;
  GPIO_InitStruct.Mode = LL_GPIO_MODE_INPUT;
  GPIO_InitStruct.Pull = LL_GPIO_PULL_NO;
  LL_GPIO_Init(GPIOE, &GPIO_InitStruct);

}

/* USER CODE BEGIN 4 */
void stopAllPhase(void){
	LL_TIM_CC_DisableChannel(TIM1, LL_TIM_CHANNEL_CH1);
	LL_TIM_CC_DisableChannel(TIM1, LL_TIM_CHANNEL_CH1N);
	LL_TIM_CC_DisableChannel(TIM1, LL_TIM_CHANNEL_CH2);
	LL_TIM_CC_DisableChannel(TIM1, LL_TIM_CHANNEL_CH2N);
	LL_TIM_CC_DisableChannel(TIM1, LL_TIM_CHANNEL_CH3);
	LL_TIM_CC_DisableChannel(TIM1, LL_TIM_CHANNEL_CH3N);
}

void startSequence(void){
	LL_TIM_CC_EnableChannel(TIM1, LL_TIM_CHANNEL_CH2);
	LL_TIM_CC_EnableChannel(TIM1, LL_TIM_CHANNEL_CH2N);
	LL_TIM_OC_SetCompareCH2(TIM1, 50);
	LL_TIM_CC_EnableChannel(TIM1, LL_TIM_CHANNEL_CH1);
	LL_TIM_CC_EnableChannel(TIM1, LL_TIM_CHANNEL_CH1N);
	LL_TIM_OC_SetCompareCH1(TIM1, 0);

	LL_mDelay(50);

	stopAllPhase();

	LL_mDelay(150);

	LL_TIM_CC_EnableChannel(TIM1, LL_TIM_CHANNEL_CH3);
	LL_TIM_CC_EnableChannel(TIM1, LL_TIM_CHANNEL_CH3N);
	LL_TIM_OC_SetCompareCH3(TIM1, 50);
	LL_TIM_CC_EnableChannel(TIM1, LL_TIM_CHANNEL_CH1);
	LL_TIM_CC_EnableChannel(TIM1, LL_TIM_CHANNEL_CH1N);
	LL_TIM_OC_SetCompareCH1(TIM1, 0);

	LL_mDelay(50);

	stopAllPhase();

	LL_mDelay(150);

	LL_TIM_CC_EnableChannel(TIM1, LL_TIM_CHANNEL_CH3);
	LL_TIM_CC_EnableChannel(TIM1, LL_TIM_CHANNEL_CH3N);
	LL_TIM_OC_SetCompareCH3(TIM1, 50);
	LL_TIM_CC_EnableChannel(TIM1, LL_TIM_CHANNEL_CH2);
	LL_TIM_CC_EnableChannel(TIM1, LL_TIM_CHANNEL_CH2N);
	LL_TIM_OC_SetCompareCH2(TIM1, 0);

	LL_mDelay(50);

	stopAllPhase();

	LL_mDelay(1000);

	LL_TIM_CC_EnableChannel(TIM1, LL_TIM_CHANNEL_CH1);
	LL_TIM_CC_EnableChannel(TIM1, LL_TIM_CHANNEL_CH1N);
	LL_TIM_OC_SetCompareCH2(TIM1, 50);
	LL_TIM_CC_EnableChannel(TIM1, LL_TIM_CHANNEL_CH2);
	LL_TIM_CC_EnableChannel(TIM1, LL_TIM_CHANNEL_CH2N);
	LL_TIM_OC_SetCompareCH3(TIM1, 0);

	LL_mDelay(50);

	stopAllPhase();

	LL_mDelay(150);

	LL_TIM_CC_EnableChannel(TIM1, LL_TIM_CHANNEL_CH3);
	LL_TIM_CC_EnableChannel(TIM1, LL_TIM_CHANNEL_CH3N);
	LL_TIM_OC_SetCompareCH2(TIM1, 50);
	LL_TIM_CC_EnableChannel(TIM1, LL_TIM_CHANNEL_CH2);
	LL_TIM_CC_EnableChannel(TIM1, LL_TIM_CHANNEL_CH2N);
	LL_TIM_OC_SetCompareCH2(TIM1, 0);

	LL_mDelay(50);

	stopAllPhase();

	LL_mDelay(150);

	LL_TIM_CC_EnableChannel(TIM1, LL_TIM_CHANNEL_CH1);
	LL_TIM_CC_EnableChannel(TIM1, LL_TIM_CHANNEL_CH1N);
	LL_TIM_OC_SetCompareCH2(TIM1, 50);
	LL_TIM_CC_EnableChannel(TIM1, LL_TIM_CHANNEL_CH2);
	LL_TIM_CC_EnableChannel(TIM1, LL_TIM_CHANNEL_CH2N);
	LL_TIM_OC_SetCompareCH3(TIM1, 0);

	LL_mDelay(50);

	stopAllPhase();

	LL_mDelay(2000);
}
/* USER CODE END 4 */

void Error_Handler(void)
{
  __disable_irq();
  while (1)
  {
  }
}
